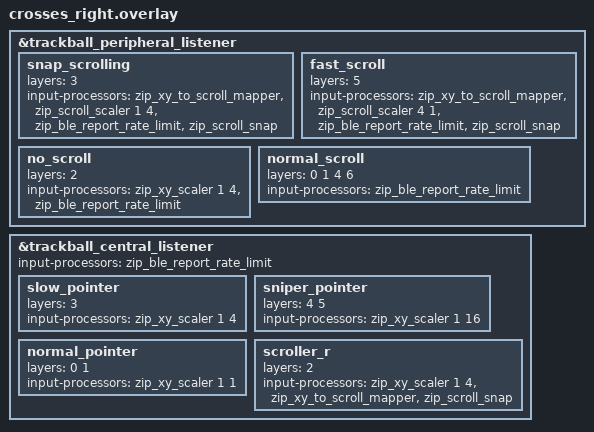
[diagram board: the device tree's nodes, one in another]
&trackball_peripheral_listener {
  status = "okay";
  snap_scrolling {
    layers = <3>;
    input-processors
      = <&zip_xy_to_scroll_mapper>
      , <&zip_scroll_scaler 1 4>
      , <&zip_ble_report_rate_limit>
	  , <&zip_scroll_snap>              //  snap to a direction for macos
	  ;
  };
    fast_scroll {
    layers = <5>;
    input-processors
      = <&zip_xy_to_scroll_mapper>
      , <&zip_scroll_scaler 4 1>
      , <&zip_ble_report_rate_limit>
	  , <&zip_scroll_snap>              //  snap to a direction for macos
	  ;
  };
    no_scroll {
    layers = <2>;
    input-processors 
      = <&zip_xy_scaler 1 4> 
	  // <&zip_xy_to_scroll_mapper>
      // <&zip_scroll_scaler 4 1>
      , <&zip_ble_report_rate_limit>
	  //, <&zip_scroll_snap>              //  snap to a direction for macos
	  ;
  };

  	normal_scroll {
    layers = <0 1 4 6>;  /* list every layer where mouse should work */
    input-processors = <&zip_ble_report_rate_limit>;
  };
};


&trackball_central_listener {
	input-processors = <&zip_ble_report_rate_limit>;

   	slow_pointer: slow_pointer{
	    layers = <3>;
	    input-processors =
	        <&zip_xy_scaler 1 4> //1 4
		//,	<&zip_xy_to_scroll_mapper>	      
		//, <&zip_ble_report_rate_limit>
		;
	  };

    sniper_pointer: sniper_pointer {
			layers           = <4 5>;
			input-processors =
				  <&zip_xy_scaler 1 16>           // Scales the scroll speed
			   //,<&zip_xy_to_scroll_mapper>      // Converts XY movement to scroll events 
               //,<&zip_scroll_snap>              //  snap to a direction for macos
			   //,<&zip_scroll_transform (INPUT_TRANSFORM_Y_INVERT)> // Inverts the scroll direction
				 ;
		};
	normal_pointer: normal_pointer {
			layers           = <0 1>;
			input-processors = <&zip_xy_scaler 1 1>;
		};

	scroller_r: scroller_r {
		layers           = <2>;
		input-processors 
			= <&zip_xy_scaler 1 4>
			, <&zip_xy_to_scroll_mapper>      // Converts XY movement to scroll events 
            , <&zip_scroll_snap>              //  snap to a direction for macos
			;
	};
};
